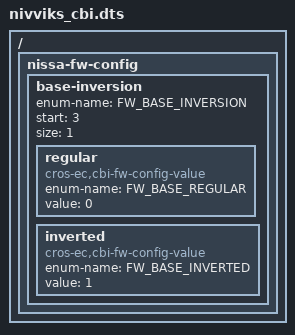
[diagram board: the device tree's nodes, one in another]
/* Copyright 2022 The Chromium OS Authors. All rights reserved.
 * Use of this source code is governed by a BSD-style license that can be
 * found in the LICENSE file.
 */

/ {
  /* Nivviks-specific fw_config fields. */
	nissa-fw-config {
		/*
		 * FW_CONFIG field to describe mainboard orientation in chassis.
		 */
		base-inversion {
			enum-name = "FW_BASE_INVERSION";
			start = <3>;
			size = <1>;

			regular {
				compatible = "cros-ec,cbi-fw-config-value";
				enum-name = "FW_BASE_REGULAR";
				value = <0>;
			};
			inverted {
				compatible = "cros-ec,cbi-fw-config-value";
				enum-name = "FW_BASE_INVERTED";
				value = <1>;
			};
		};
	};
};
